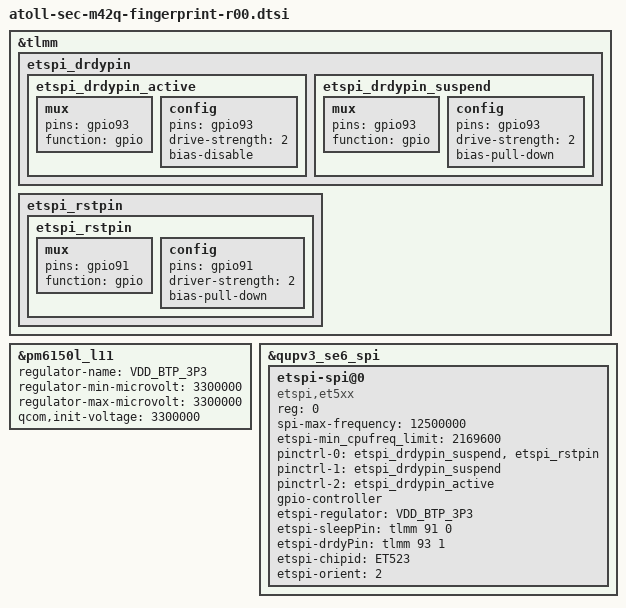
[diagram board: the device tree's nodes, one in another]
/* Copyright (c) 2013-2019, The Linux Foundation. All rights reserved.
 *
 * This program is free software; you can redistribute it and/or modify
 * it under the terms of the GNU General Public License version 2 and
 * only version 2 as published by the Free Software Foundation.
 *
 * This program is distributed in the hope that it will be useful,
 * but WITHOUT ANY WARRANTY; without even the implied warranty of
 * MERCHANTABILITY or FITNESS FOR A PARTICULAR PURPOSE.  See the
 * GNU General Public License for more details.
 */

&tlmm {
	etspi_drdypin {
		etspi_drdypin_active: etspi_drdypin_active {
			mux {
				pins = "gpio93";
				function = "gpio";
			};
			config {
				pins = "gpio93";
				drive-strength = <2>;
				bias-disable;
			};
		};
		etspi_drdypin_suspend: etspi_drdypin_suspend {
			mux {
				pins = "gpio93";
				function = "gpio";
			};
			config {
				pins = "gpio93";
				drive-strength = <2>;
				bias-pull-down;
			};
		};
	};

	etspi_rstpin {
		etspi_rstpin: etspi_rstpin {
			mux {
				pins = "gpio91";
				function = "gpio";
			};
			config {
				pins = "gpio91";
				driver-strength = <2>;
				bias-pull-down;
			};
		};
	};
};

&pm6150l_l11 {
	regulator-name = "VDD_BTP_3P3";
	regulator-min-microvolt = <3300000>;
	regulator-max-microvolt = <3300000>;
	qcom,init-voltage = <3300000>;
};

&qupv3_se6_spi {
	status = "okay";

	etspi-spi@0 {
		compatible = "etspi,et5xx";
		reg = <0>;
		spi-max-frequency = <12500000>;
		etspi-min_cpufreq_limit = <2169600>;

		pinctrl-names = "default", "sleep", "idle";
		pinctrl-0 = <&etspi_drdypin_suspend &etspi_rstpin>;
		pinctrl-1 = <&etspi_drdypin_suspend>;
		pinctrl-2 = <&etspi_drdypin_active>;

		gpio-controller;
		#gpio-cells = <2>;

		etspi-regulator = "VDD_BTP_3P3";
		etspi-sleepPin = <&tlmm 91 0>;
		etspi-drdyPin = <&tlmm 93 1>;
		etspi-chipid = "ET523";
		etspi-orient = <2>;
	};
};
